# CY8C5888LTI_LP097 register map
File version: 0.1
CY8C58LP
Registers are 8-bit, read-write, no defined reset value unless marked. A register's access mark holds for its fields unless they carry their own. Offsets are from the block's base; lines under a group give offsets from that group; [hi:lo] are bit positions; {n}, {i} and the like mark numbered series; 'fields as' and 'values as' point back to an identical list; <NAME> marks a mode.

## Memory map
0x00000000 Timer_Stopur
0x00000000 Timer_LCD
0x00000000 I2C_1
0x00000000 SPIMOutCtrl
0x00000000 SPIS
0x00000000 Timer4
0x00000000 Timer5
0x00000000 Timer1
0x00000000 Timer3
0x00000000 Timer2
0x00000000 ADC_SAR_1 — SAR ADC
0x00000000 UART_1 — UART

## Timer_Stopur
Base 0x00000000
0x4000640C Timer_Stopur_COUNTER 16-bit — UDB.A0 - Current Down Counter Value
0x4000642C Timer_Stopur_PERIOD 16-bit — UDB.D0 - Assigned Period
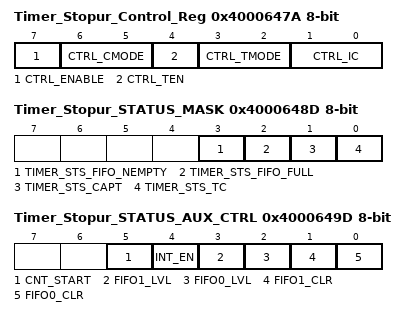
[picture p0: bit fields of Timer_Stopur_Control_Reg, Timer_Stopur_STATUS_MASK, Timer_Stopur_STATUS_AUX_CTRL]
0x4000647A Timer_Stopur_Control_Reg — UDB Control Register - Assigned Control Register Value
  [7] CTRL_ENABLE — Enable the Timer
  [6:5] CTRL_CMODE — Capture Mode
  [4] CTRL_TEN — Trigger Enable Bit
  [3:2] CTRL_TMODE — Trigger Mode
  [1:0] CTRL_IC — Interrupt Count
0x4000648D Timer_Stopur_STATUS_MASK — UDB Status bits Interrupt Mask Enable Register
  [3] TIMER_STS_FIFO_NEMPTY ro — FIFO Empty status
  [2] TIMER_STS_FIFO_FULL ro — FIFO Full Status
  [1] TIMER_STS_CAPT ro — Enables the Interrupt on Capture
  [0] TIMER_STS_TC ro — Enables the Interrupt on TC
0x4000649D Timer_Stopur_STATUS_AUX_CTRL — UDB Auxilliary Control Register
  [5] CNT_START — FIFO0 clear
    0=E_CNT_START0 (Disable counter); 1=E_CNT_START1 (Enable counter)
  [4] INT_EN
    0=E_INT_EN0 (Interrupt disabled); 1=E_INT_EN1 (Interrupt enabled)
  [3] FIFO1_LVL — FIFO level
    0=E_FIFO_LVL_0 (FIFO LVL: input mode: FIFO not full; output mode: FIFO not empty); 1=E_FIFO_LVL_1 (FIFO LVL: input mode: FIFO at least 1/2 empty; output mode: FIFO at least 1/2 full)
  [2] FIFO0_LVL — FIFO level
    values as FIFO1_LVL
  [1] FIFO1_CLR — FIFO1 clear
    0=E_FIFO_CLR_0 (Normal FIFO operation); 1=E_FIFO_CLR_1 (Clear FIFO state)
  [0] FIFO0_CLR — FIFO0 clear
    values as FIFO1_CLR

## Timer_LCD
Base 0x00000000
0x4000640A Timer_LCD_COUNTER 16-bit — UDB.A0 - Current Down Counter Value
0x4000642A Timer_LCD_PERIOD 16-bit — UDB.D0 - Assigned Period
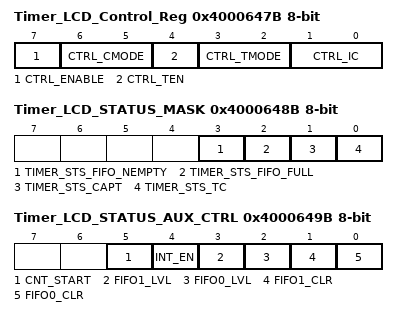
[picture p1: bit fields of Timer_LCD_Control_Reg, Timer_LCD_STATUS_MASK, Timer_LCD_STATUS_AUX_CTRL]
0x4000647B Timer_LCD_Control_Reg — UDB Control Register - Assigned Control Register Value
  [7] CTRL_ENABLE — Enable the Timer
  [6:5] CTRL_CMODE — Capture Mode
  [4] CTRL_TEN — Trigger Enable Bit
  [3:2] CTRL_TMODE — Trigger Mode
  [1:0] CTRL_IC — Interrupt Count
0x4000648B Timer_LCD_STATUS_MASK — UDB Status bits Interrupt Mask Enable Register
  [3] TIMER_STS_FIFO_NEMPTY ro — FIFO Empty status
  [2] TIMER_STS_FIFO_FULL ro — FIFO Full Status
  [1] TIMER_STS_CAPT ro — Enables the Interrupt on Capture
  [0] TIMER_STS_TC ro — Enables the Interrupt on TC
0x4000649B Timer_LCD_STATUS_AUX_CTRL — UDB Auxilliary Control Register
  [5] CNT_START — FIFO0 clear
    0=E_CNT_START0 (Disable counter); 1=E_CNT_START1 (Enable counter)
  [4] INT_EN
    0=E_INT_EN0 (Interrupt disabled); 1=E_INT_EN1 (Interrupt enabled)
  [3] FIFO1_LVL — FIFO level
    0=E_FIFO_LVL_0 (FIFO LVL: input mode: FIFO not full; output mode: FIFO not empty); 1=E_FIFO_LVL_1 (FIFO LVL: input mode: FIFO at least 1/2 empty; output mode: FIFO at least 1/2 full)
  [2] FIFO0_LVL — FIFO level
    values as FIFO1_LVL
  [1] FIFO1_CLR — FIFO1 clear
    0=E_FIFO_CLR_0 (Normal FIFO operation); 1=E_FIFO_CLR_1 (Clear FIFO state)
  [0] FIFO0_CLR — FIFO0 clear
    values as FIFO1_CLR

## SPIMOutCtrl
Base 0x00000000
0x40006472 SPIMOutCtrl_CONTROL_REG

## SPIS
Base 0x00000000
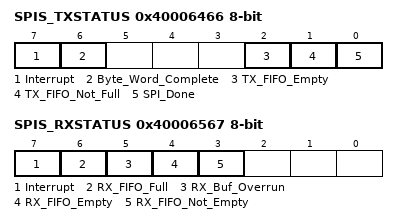
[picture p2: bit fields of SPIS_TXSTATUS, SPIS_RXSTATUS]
0x40006466 SPIS_TXSTATUS
  [7] Interrupt ro — Set when interrupt occurs
  [6] Byte_Word_Complete ro — Set when a byte/word transmit has completed
  [2] TX_FIFO_Empty ro — Set when the TX Data FIFO is empty
  [1] TX_FIFO_Not_Full ro — Set when the TX Data FIFO is not full
  [0] SPI_Done ro — Set when all of the data in the transmit FIFO has been sent. Set when Byte/Word Complete has been set and TX Data FIFO is empty
0x40006506 SPIS_TX_DATA
0x40006506 SPIS_RX_DATA
0x40006567 SPIS_RXSTATUS
  [7] Interrupt ro — Set when interrupt occurs
  [6] RX_FIFO_Full ro — Set when the RX Data FIFO is full
  [5] RX_Buf_Overrun ro — Set when RX Data has overrun the 4 byte/word FIFO without being moved to the RX buffer cmemory array (if one exists)
  [4] RX_FIFO_Empty ro — Set when the RX Data FIFO is empty
  [3] RX_FIFO_Not_Empty ro — Set when the RX Data FIFO is not empty. That is, at least one byte/word is in the RX FIFO
